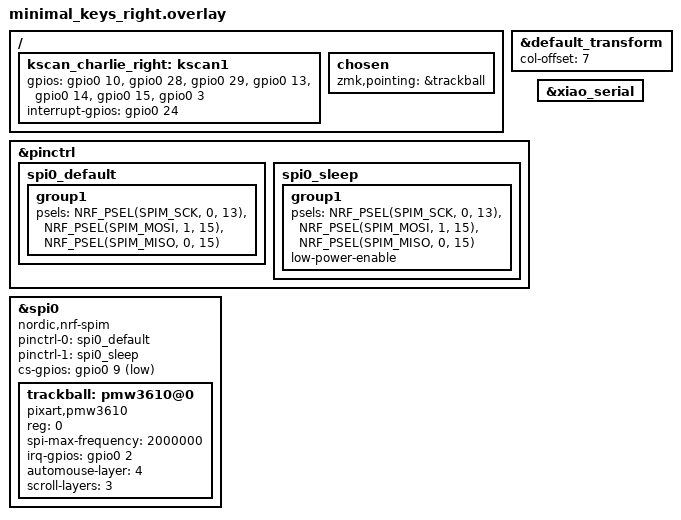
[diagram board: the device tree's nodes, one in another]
#include "minimal_keys.dtsi"

&default_transform {
    col-offset = <7>;  // 右側の開始列を7に設定
};

/ {
     kscan_charlie_right: kscan1 {
        gpios = < &gpio0 10 GPIO_ACTIVE_HIGH >,
                < &gpio0 28 GPIO_ACTIVE_HIGH >,
                < &gpio0 29 GPIO_ACTIVE_HIGH >,
                < &gpio0 13 GPIO_ACTIVE_HIGH >,
                < &gpio0 14 GPIO_ACTIVE_HIGH >,
                < &gpio0 15 GPIO_ACTIVE_HIGH >,
                < &gpio0 3 GPIO_ACTIVE_HIGH >;
        interrupt-gpios = < &gpio0 24 (GPIO_PULL_DOWN | GPIO_ACTIVE_HIGH) >;
        status = "okay";
    };

    // トラックボール設定
    chosen {
        zmk,pointing = &trackball;
    };
};

// SPI設定
&pinctrl {
    spi0_default: spi0_default {
        group1 {
            psels = <NRF_PSEL(SPIM_SCK, 0, 13)>,    // P0.13 (D8/SCK)
                  <NRF_PSEL(SPIM_MOSI, 1, 15)>,   // P1.15 (D10/MOSI)
                  <NRF_PSEL(SPIM_MISO, 0, 15)>;   // P0.15 (D9/MISO)
        };
    };
    spi0_sleep: spi0_sleep {
        group1 {
            psels = <NRF_PSEL(SPIM_SCK, 0, 13)>,
                  <NRF_PSEL(SPIM_MOSI, 1, 15)>,
                  <NRF_PSEL(SPIM_MISO, 0, 15)>;
            low-power-enable;
        };
    };
};
&xiao_serial { status = "okay"; };

&spi0 {
    status = "okay";
    compatible = "nordic,nrf-spim";
    pinctrl-0 = <&spi0_default>;
    pinctrl-1 = <&spi0_sleep>;
    pinctrl-names = "default", "sleep";

    cs-gpios = <&gpio0 9 GPIO_ACTIVE_LOW>;  // P0.09 (NFC1)

    trackball: pmw3610@0 {
        status = "okay";
        compatible = "pixart,pmw3610";
        reg = <0>;
        spi-max-frequency = <2000000>;
        irq-gpios = <&gpio0 2 GPIO_ACTIVE_HIGH>;  // P0.03 (D1/A1)
        
        automouse-layer = <4>;
        scroll-layers = <3>;
    };
};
